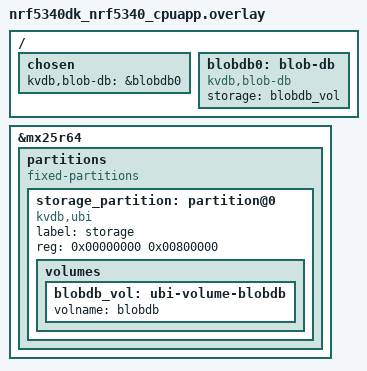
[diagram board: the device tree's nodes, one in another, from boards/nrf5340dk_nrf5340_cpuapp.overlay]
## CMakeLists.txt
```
#-------------------------------------------------------------------------------
# blob_db performance benchmark app
#
# Copyright (c) 2026
# SPDX-License-Identifier: Apache-2.0

cmake_minimum_required(VERSION 3.13.1)
find_package(Zephyr REQUIRED HINTS $ENV{ZEPHYR_BASE})

project(app_perf LANGUAGES C)

target_sources(app PRIVATE src/main.c)
```

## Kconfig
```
# blob_db perf app — Kconfig entry point.

menu "Zephyr"
source "Kconfig.zephyr"
endmenu

module = APP_PERF
module-str = APP_PERF
source "subsys/logging/Kconfig.template.log_config"

config APP_PERF_N_OPS
	int "Number of add/read operations per run"
	default 100
	range 10 1000
	help
	  Size of the benchmark: this many nodes are added (then read back
	  by traversal). Runtime grows roughly linearly.

config APP_PERF_VAL_LEN
	int "Per-node payload size in bytes"
	default 24
	range 0 240
	help
	  Payload bytes stored in each list node (in addition to the 8-byte
	  next_id header). Keep the total node size under
	  CONFIG_BLOB_DB_MAX_PAYLOAD_LEN.

if BLOB_DB_LARGE_PAYLOADS

config APP_PERF_OBJ_LEN
	int "Large-object size in bytes"
	default 65536
	help
	  Size of each object in the large-object phases. Must be within
	  CONFIG_BLOB_DB_MAX_OBJECT_LEN. Run the app twice with different
	  values to see the size sweep that matters: partial-write cost should
	  stay flat while whole-object rewrite cost grows with this number.

config APP_PERF_N_LARGE
	int "Number of large objects"
	default 4
	range 1 64
	help
	  Kept small: each object costs OBJ_LEN of writes per phase, and on
	  64 KB-sector QSPI NOR a cold pass also pays a sector erase per
	  segment bucket.

config APP_PERF_N_PART
	int "Number of partial (pread/pwrite) operations per phase"
	default 32
	range 4 4096
	help
	  Timing is at millisecond resolution, so this needs to be large
	  enough that a phase totals tens of milliseconds. On real NOR one
	  partial write is tens of ms, so 32 is already seconds; on native_sim
	  without CONFIG_FLASH_SIMULATOR_SIMULATE_TIMING raise it substantially
	  or the phase rounds to zero.

config APP_PERF_PART_LEN
	int "Bytes touched by each partial operation"
	default 64
	range 1 4096
	help
	  Deliberately far smaller than a segment: the point of the partial
	  phases is the ratio between touching a few bytes and rewriting the
	  whole object.

endif # BLOB_DB_LARGE_PAYLOADS
```

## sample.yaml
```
sample:
  description: blob_db performance benchmark
  name: blob-db-perf
common:
  build_only: true
tests:
  perf.default: {}
```

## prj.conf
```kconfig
CONFIG_LOG=y
CONFIG_APP_PERF_LOG_LEVEL_INF=y

# blob_db is switched on by the kvdb,blob-db node in boards/<board>.overlay.

# Keep blob_db quiet so the timing loop is not perturbed by per-op log
# messages (and UART overrun does not eat the benchmark line).
CONFIG_BLOB_DB_LOG_LEVEL_WRN=y

# blob_db stack-allocates a slot buffer per op; roomy main stack keeps
# native_sim's frame overhead safe alongside it.
CONFIG_MAIN_STACK_SIZE=32768

# Exercise the large-object paths (segmented storage, pread, pwrite) as well
# as the small-blob ones. Raises BLOB_DB_MAX_PAYLOAD_LEN's default to 2016 and
# bumps the on-flash format major to 2 — neither affects the small-blob phases,
# whose slot sizes follow the payload actually written.
CONFIG_BLOB_DB_LARGE_PAYLOADS=y

# Count flash operations and bytes. On native_sim this is the only meaningful
# output the benchmark has — the flash simulator models no latency, so every
# wall-clock figure rounds to zero.
CONFIG_BLOB_DB_IOSTATS=y
```

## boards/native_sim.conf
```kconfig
# blob_db_erase_all() invalidates bucket headers by programming 0x00 over
# already-programmed magic bytes (1->0 only — legal on real NOR without an
# erase). The flash simulator rejects program-over-non-erased by default;
# allow it so the benchmark's erase_all-between-phases works on native_sim.
CONFIG_FLASH_SIMULATOR_DOUBLE_WRITES=y

# UBI static PEB pool: native_sim's 8 MB partition in the simulator's default
# 4 KB erase blocks is 2048 PEBs, less the 2 reserved for headers.
CONFIG_UBI_MAX_NR_OF_DATA_PEBS=2046
```

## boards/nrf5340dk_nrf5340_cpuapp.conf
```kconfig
CONFIG_BLOB_DB_SECTOR_BUF_SIZE=65536

# zephyr-ubi's heap: 8 B per erase block (128 of 64 KB here, so 1 KB) plus a
# handle and scratch buffer at attach and a second pair during a format. The
# default assumes 4 KB blocks and would reserve 20 KB.
CONFIG_HEAP_MEM_POOL_ADD_SIZE_BLOB_DB_UBI=6144
```

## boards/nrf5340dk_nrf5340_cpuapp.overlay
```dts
/*
 * Same partition move as the demo app: run the benchmark against the on-board
 * MX25R64 QSPI NOR (8 MB, 64 KB sectors) so the numbers reflect real flash.
 */

/delete-node/ &storage_partition;

&mx25r64 {
	partitions {
		compatible = "fixed-partitions";
		#address-cells = <1>;
		#size-cells = <1>;

		storage_partition: partition@0 {
			compatible = "kvdb,ubi";
			label = "storage";
			reg = <0x00000000 0x00800000>;

			volumes {
				blobdb_vol: ubi-volume-blobdb {
					volname = "blobdb";
				};
			};
		};
	};
};

/*
 * The blob_db store on the volume above. No "automount": this program mounts,
 * formats and unmounts the store itself, which keeps working exactly as
 * before (doc/proposals/2026-10-12-devicetree-configuration.md §3.5).
 */
/ {
	chosen {
		kvdb,blob-db = &blobdb0;
	};

	blobdb0: blob-db {
		compatible = "kvdb,blob-db";
		storage = <&blobdb_vol>;
	};
};
```

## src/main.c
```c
/*
 * Copyright (c) 2026
 * SPDX-License-Identifier: Apache-2.0
 *
 * blob_db performance benchmark.
 *
 * Builds a singly-linked list on top of the blob_db API:
 *   - each node is one blob: { uint64_t next_id; uint8_t val[VAL_LEN]; }
 *   - the head id is stored at BLOB_DB_ROOT_ID (empty root == empty list)
 *
 * Four workloads are measured. Each phase runs erase_all() followed by
 * blob_db_maintain() until nothing is left, so the timed loop measures the
 * append-only write path — the erases blob_db can do ahead are paid up-front
 * and reported separately.
 *   maint   — on flash_area, format every fresh bucket (one 64 KB sector
 *             erase each on mx25r64); on UBI, reclaim the blocks waiting
 *             for an erase. Either way the append/prepend loops below find
 *             an erased block for every bucket they first write.
 *   prepend — alloc_id + bind(new, next=head) + update(root=new_id)
 *   append  — alloc_id + bind(new, next=0) + update(prev_tail, next=new_id)
 *             (O(1) via a caller-side tail cache)
 *   read    — traverse from head, get() every node
 *   update  — rewrite the payload of every existing node in place
 *
 * With CONFIG_BLOB_DB_LARGE_PAYLOADS a second group of phases exercises
 * objects too large for one slot — stored as segments plus an index record —
 * and the partial-access API that exists for them:
 *   lg write   — blob_db_update() of N_LARGE objects of OBJ_LEN each, onto
 *                unformatted buckets, so the sector erases are included
 *   lg rewrite — the same objects written again over now-formatted buckets;
 *                the gap against "lg write" IS the erase cost, measured
 *                rather than assumed
 *   lg read    — blob_db_read() over each object in PART_LEN windows
 *   lg pread   — N_PART reads at pseudo-random offsets, reported per quartile
 *                of the object. Contract R2 says cost is independent of
 *                offset; four similar numbers support that, a rising series
 *                falsifies it
 *   lg pwrite  — N_PART partial writes at pseudo-random offsets. Compare
 *                us/op against "lg rewrite": that ratio is the whole reason
 *                blob_db_write exists, and it should grow with OBJ_LEN
 *                (rewrite) while staying flat (pwrite)
 *
 * Wall-clock is via k_uptime_delta(); ops/sec is derived at millisecond
 * resolution — for flash operations that costs less than 1 % vs a raw
 * cycle counter, and stays sane over runs measured in seconds.
 *
 * CAVEAT for native_sim: the flash simulator does not model erase or program
 * latency unless CONFIG_FLASH_SIMULATOR_SIMULATE_TIMING is set with the
 * MIN_*_TIME_US knobs calibrated to the target part. Without that, these
 * phases measure CPU and memcpy, not storage — which will flatter paths that
 * move fewer bytes and penalise paths that issue more transactions. Run on
 * hardware, or calibrate the simulator, before drawing conclusions.
 */

#include <errno.h>
#include <inttypes.h>
#include <stdint.h>
#include <string.h>

#include <zephyr/kernel.h>
#include <zephyr/logging/log.h>
#include <zephyr/sys/printk.h>

#include <app/lib/blob_db.h>
#include <app/lib/blob_db_iostats.h>

#include <zephyr/app_version.h>

#ifdef CONFIG_ARCH_POSIX
#include "posix_board_if.h"   /* posix_exit() — end the sim run cleanly */
#endif

LOG_MODULE_REGISTER(app_perf, CONFIG_APP_PERF_LOG_LEVEL);

#define N_OPS   CONFIG_APP_PERF_N_OPS
#define VAL_LEN CONFIG_APP_PERF_VAL_LEN

struct __packed node {
	uint64_t next_id;
	uint8_t  val[VAL_LEN];
};

BUILD_ASSERT(sizeof(struct node) <= CONFIG_BLOB_DB_MAX_PAYLOAD_LEN,
	     "node exceeds CONFIG_BLOB_DB_MAX_PAYLOAD_LEN");

/* --- list ops on top of blob_db --------------------------------------- */

static int list_head(uint64_t *head_out)
{
	uint64_t head = 0;
	size_t got;
	int rc = blob_db_get(BLOB_DB_ROOT_ID, &head, sizeof(head), &got);

	if (rc < 0) {
		return rc;
	}
	*head_out = (got == sizeof(head)) ? head : 0;
	return 0;
}

static int list_prepend(uint64_t new_id, const uint8_t *val)
{
	uint64_t head;
	int rc = list_head(&head);

	if (rc < 0) {
		return rc;
	}

	struct node n = { .next_id = head };

	memcpy(n.val, val, VAL_LEN);

	rc = blob_db_update(new_id, &n, sizeof(n));
	if (rc < 0) {
		return rc;
	}
	return blob_db_update(BLOB_DB_ROOT_ID, &new_id, sizeof(new_id));
}

/* Append `new_id` after `prev_tail`, or at the head if the list is empty.
 * Two flash writes per call (same as prepend); the caller keeps track of
 * the current tail to avoid an O(n) walk on every append. */
static int list_append(uint64_t new_id, uint64_t prev_tail, const uint8_t *val)
{
	struct node n = { .next_id = 0 };

	memcpy(n.val, val, VAL_LEN);

	int rc = blob_db_update(new_id, &n, sizeof(n));

	if (rc < 0) {
		return rc;
	}

	if (prev_tail == 0) {
		/* Empty list — new node becomes the head. */
		return blob_db_update(BLOB_DB_ROOT_ID, &new_id, sizeof(new_id));
	}

	/* Splice new_id in after prev_tail. */
	struct node prev;
	size_t got;

	rc = blob_db_get(prev_tail, &prev, sizeof(prev), &got);
	if (rc < 0) {
		return rc;
	}
	prev.next_id = new_id;
	return blob_db_update(prev_tail, &prev, sizeof(prev));
}

/* Returns number of nodes visited (0 on empty list, negative on error). */
static int list_traverse(uint32_t *checksum_out)
{
	uint64_t cur;
	int rc = list_head(&cur);

	if (rc < 0) {
		return rc;
	}

	uint32_t sum = 0;
	int n = 0;

	while (cur != 0) {
		struct node node;
		size_t got;

		rc = blob_db_get(cur, &node, sizeof(node), &got);
		if (rc < 0) {
			return rc;
		}
		if (got != sizeof(node)) {
			LOG_ERR("bad node at id=%llu got=%zu", cur, got);
			return -EIO;
		}
		/* Fold the payload into a checksum so the compiler cannot
		 * elide the reads. */
		for (size_t i = 0; i < VAL_LEN; i++) {
			sum = sum * 33u + node.val[i];
		}
		n++;
		cur = node.next_id;
	}
	if (checksum_out) {
		*checksum_out = sum;
	}
	return n;
}

/* --- benchmark harness ------------------------------------------------- */

/* Run blob_db_maintain() until nothing is left; returns the steps taken. */
static int maintain_all(void)
{
	struct blob_db_maint_result res;
	int steps = 0;

	do {
		const int rc = blob_db_maintain(1, &res);

		if (rc < 0) {
			return rc;
		}
		steps += (int)res.performed;
	} while (res.more);
	return steps;
}

static void bench_line(const char *what, int ops, int64_t ms)
{
	/* Print ops/s with three fractional digits so sub-1-op/s workloads
	 * (e.g. a cold add pass on QSPI) still show a meaningful number. */
	uint64_t milli_ops_per_s =
		(ms > 0) ? (uint64_t)ops * 1000000ULL / (uint64_t)ms : 0;
	uint64_t us_per_op =
		(ops > 0) ? (uint64_t)ms * 1000ULL / (uint64_t)ops : 0;

	printk("bench %-6s : %4d ops in %7" PRId64 " ms  -> "
	       "%4u.%03u ops/s  (%9llu us/op)\n",
	       what, ops, ms,
	       (unsigned)(milli_ops_per_s / 1000),
	       (unsigned)(milli_ops_per_s % 1000),
	       (unsigned long long)us_per_op);
}

#if defined(CONFIG_BLOB_DB_IOSTATS)
/* Flash actually touched by the phase just measured.
 *
 * On native_sim this is the only meaningful number the benchmark produces: the
 * flash simulator models no latency, so every wall-clock figure rounds to zero.
 * It is also the number that settles arguments wall-clock cannot — amplification
 * is a ratio of bytes, and transaction count is what a serial part charges a
 * fixed cost for. Both are printed because a change can improve one and worsen
 * the other.
 */
static struct blob_db_iostats io_mark;

static void io_reset(void)
{
	blob_db_iostats_get(&io_mark);
}

static void io_line(const char *what, size_t useful_bytes)
{
	struct blob_db_iostats now;

	blob_db_iostats_get(&now);

	const uint32_t rd = now.reads - io_mark.reads;
	const uint32_t wr = now.writes - io_mark.writes;
	const uint32_t er = now.erases - io_mark.erases;
	const uint64_t brd = now.bytes_read - io_mark.bytes_read;
	const uint64_t bwr = now.bytes_written - io_mark.bytes_written;
	/* Erase BYTES, not just calls: one call may cover one erase block or
	 * the whole partition (blob_db_erase_all() does exactly that), and a
	 * cost model fed only the call count cannot tell those apart. This is
	 * the field app_perf_l0/tools/l0_timing.py needs to charge an erase
	 * per block; captures older than it carry the count alone. */
	const uint64_t ber = now.bytes_erased - io_mark.bytes_erased;

	printk("   io %-10s: rd %6u ops/%8llu B   wr %5u ops/%8llu B   "
	       "er %4u ops/%8llu B",
	       what, rd, (unsigned long long)brd, wr,
	       (unsigned long long)bwr, er, (unsigned long long)ber);

	/* Amplification against the bytes the caller actually asked for. */
	if (useful_bytes > 0) {
		printk("   ampl rd %llu.%02llux wr %llu.%02llux",
		       (unsigned long long)(brd / useful_bytes),
		       (unsigned long long)((brd * 100 / useful_bytes) % 100),
		       (unsigned long long)(bwr / useful_bytes),
		       (unsigned long long)((bwr * 100 / useful_bytes) % 100));
	}
	printk("\n");
}
#else
#define io_reset()            ((void)0)
#define io_line(what, bytes)  ((void)0)
#endif

/* Run every workload from an empty list (erase_all) so timings are
 * apples-to-apples across phases. Returns 0 on success, negative errno on
 * blob_db failures. */
static int bench_phase_read_and_update(uint8_t *val, uint32_t *checksum)
{
	io_reset();
	int64_t t = k_uptime_get();
	int visited = list_traverse(checksum);
	int64_t t_read = k_uptime_delta(&t);

	if (visited < 0) {
		return visited;
	}
	if (visited != N_OPS) {
		LOG_ERR("traverse saw %d, expected %u", visited,
			(unsigned)N_OPS);
	}
	bench_line("read", visited, t_read);
	io_line("read", (size_t)visited * sizeof(struct node));

	/* Warm update: walk again and rewrite every node in place. The
	 * bucket is already formatted, so no sector erase runs. */
	uint64_t cur;
	int rc = list_head(&cur);

	if (rc < 0 || cur == 0) {
		return rc;
	}

	io_reset();
	t = k_uptime_get();
	int updated = 0;

	while (cur != 0) {
		struct node node;
		size_t got;

		rc = blob_db_get(cur, &node, sizeof(node), &got);
		if (rc < 0) {
			return rc;
		}
		node.val[0]++;
		rc = blob_db_update(cur, &node, sizeof(node));
		if (rc < 0) {
			return rc;
		}
		updated++;
		cur = node.next_id;
	}
	int64_t t_upd = k_uptime_delta(&t);

	bench_line("update", updated, t_upd);
	io_line("update", (size_t)updated * sizeof(struct node));

	(void)val;
	return 0;
}

/* --- large-object phases ----------------------------------------------- */
#if defined(CONFIG_BLOB_DB_LARGE_PAYLOADS)

#define OBJ_LEN   CONFIG_APP_PERF_OBJ_LEN
#define N_LARGE   CONFIG_APP_PERF_N_LARGE
#define N_PART    CONFIG_APP_PERF_N_PART
#define PART_LEN  CONFIG_APP_PERF_PART_LEN

BUILD_ASSERT(OBJ_LEN <= CONFIG_BLOB_DB_MAX_OBJECT_LEN,
	     "APP_PERF_OBJ_LEN exceeds CONFIG_BLOB_DB_MAX_OBJECT_LEN");
BUILD_ASSERT(PART_LEN <= OBJ_LEN, "APP_PERF_PART_LEN exceeds OBJ_LEN");

/* Static, not stack: OBJ_LEN is tens of kilobytes. */
static uint8_t g_obj[OBJ_LEN];
static uint8_t g_win[PART_LEN];
static uint64_t g_ids[N_LARGE];

/* Throughput line for the phases where bytes matter more than operations. */
static void bench_bytes(const char *what, int ops, size_t bytes, int64_t ms)
{
	uint64_t kb_per_s =
		(ms > 0) ? (uint64_t)bytes * 1000ULL / 1024ULL / (uint64_t)ms : 0;
	uint64_t us_per_op =
		(ops > 0) ? (uint64_t)ms * 1000ULL / (uint64_t)ops : 0;

	printk("bench %-10s: %4d ops in %7" PRId64 " ms  -> "
	       "%6llu KB/s  (%9llu us/op)\n",
	       what, ops, ms, (unsigned long long)kb_per_s,
	       (unsigned long long)us_per_op);
}

/* Deterministic offsets, so runs are comparable and a regression is not
 * masked by a different random walk. */
static uint32_t lcg(uint32_t *state)
{
	*state = (*state * 1103515245u) + 12345u;
	return *state >> 8;
}

static void fill_obj(uint8_t seed)
{
	for (size_t i = 0; i < OBJ_LEN; i++) {
		g_obj[i] = (uint8_t)((i * 31u + seed) ^ (i >> 8));
	}
}

static int bench_large(void)
{
	int rc;

	printk("\n-- large objects (OBJ_LEN=%u  N_LARGE=%u  N_PART=%u  "
	       "PART_LEN=%u) --\n",
	       (unsigned)OBJ_LEN, (unsigned)N_LARGE, (unsigned)N_PART,
	       (unsigned)PART_LEN);

	rc = blob_db_erase_all();
	if (rc < 0) {
		LOG_ERR("erase_all: %d", rc);
		return rc;
	}

	fill_obj(0x5a);

	/* Cold: buckets are unformatted, so every segment pays a sector erase.
	 * Deliberately NOT maintained — the contrast with the warm pass below
	 * is what quantifies the erase cost. */
	io_reset();
	int64_t t = k_uptime_get();

	for (int i = 0; i < N_LARGE; i++) {
		g_ids[i] = blob_db_alloc_id();
		if (g_ids[i] == 0) {
			LOG_ERR("alloc_id returned 0 at i=%d", i);
			return -EIO;
		}
		rc = blob_db_update(g_ids[i], g_obj, OBJ_LEN);
		if (rc < 0) {
			LOG_ERR("large write %d: %d", i, rc);
			return rc;
		}
	}
	bench_bytes("lg write", N_LARGE, (size_t)N_LARGE * OBJ_LEN,
		    k_uptime_delta(&t));
	io_line("lg write", (size_t)N_LARGE * OBJ_LEN);

	/* Confirm the store agrees about what was written before timing reads. */
	size_t reported = 0;

	rc = blob_db_size(g_ids[0], &reported);
	if (rc < 0 || reported != OBJ_LEN) {
		LOG_ERR("size mismatch: rc=%d got=%zu want=%u", rc, reported,
			(unsigned)OBJ_LEN);
		return (rc < 0) ? rc : -EIO;
	}

	/* Warm: same objects, buckets now formatted. */
	fill_obj(0xa5);
	io_reset();
	t = k_uptime_get();
	for (int i = 0; i < N_LARGE; i++) {
		rc = blob_db_update(g_ids[i], g_obj, OBJ_LEN);
		if (rc < 0) {
			LOG_ERR("large rewrite %d: %d", i, rc);
			return rc;
		}
	}
	const int64_t t_rewrite = k_uptime_delta(&t);

	bench_bytes("lg rewrite", N_LARGE, (size_t)N_LARGE * OBJ_LEN, t_rewrite);
	io_line("lg rewrite", (size_t)N_LARGE * OBJ_LEN);

	/* Sequential read through a small window, checksummed so the reads
	 * cannot be elided and a wrong byte shows up as a wrong sum. */
	uint32_t sum = 0;

	io_reset();
	t = k_uptime_get();
	for (int i = 0; i < N_LARGE; i++) {
		for (size_t off = 0; off < OBJ_LEN; off += PART_LEN) {
			size_t got = 0;

			rc = blob_db_read(g_ids[i], off, g_win, PART_LEN, &got);
			if (rc < 0) {
				LOG_ERR("lg read %d@%zu: %d", i, off, rc);
				return rc;
			}
			for (size_t b = 0; b < got; b++) {
				sum = sum * 33u + g_win[b];
			}
		}
	}
	bench_bytes("lg read", N_LARGE * (int)(OBJ_LEN / PART_LEN),
		    (size_t)N_LARGE * OBJ_LEN, k_uptime_delta(&t));
	io_line("lg read", (size_t)N_LARGE * OBJ_LEN);
	printk("lg read checksum: 0x%08x\n", sum);

	/* Offset independence (contract R2): same operation, four bands of the
	 * object. Similar numbers support the claim; a rising series refutes it. */
	for (int q = 0; q < 4; q++) {
		const size_t base = (size_t)q * (OBJ_LEN / 4);
		const size_t span = (OBJ_LEN / 4) - PART_LEN;
		uint32_t rnd = 0x1234u + (uint32_t)q;
		char label[16];

		io_reset();
		t = k_uptime_get();
		for (int n = 0; n < N_PART; n++) {
			const size_t off = base + (span ? (lcg(&rnd) % span) : 0);
			size_t got = 0;

			rc = blob_db_read(g_ids[n % N_LARGE], off, g_win,
					  PART_LEN, &got);
			if (rc < 0) {
				LOG_ERR("pread q%d: %d", q, rc);
				return rc;
			}
		}
		(void)snprintk(label, sizeof(label), "lg pread q%d", q);
		bench_bytes(label, N_PART, (size_t)N_PART * PART_LEN,
			    k_uptime_delta(&t));
		io_line(label, (size_t)N_PART * PART_LEN);
	}

	/* Partial writes. The number to compare against "lg rewrite": this is
	 * the difference between touching one segment and rewriting the object. */
	uint32_t rnd = 0xbeefu;

	io_reset();
	t = k_uptime_get();
	for (int n = 0; n < N_PART; n++) {
		const size_t off = lcg(&rnd) % (OBJ_LEN - PART_LEN);

		memset(g_win, (uint8_t)n, PART_LEN);
		rc = blob_db_write(g_ids[n % N_LARGE], off, g_win, PART_LEN);
		if (rc < 0) {
			LOG_ERR("pwrite %d: %d", n, rc);
			return rc;
		}
	}
	const int64_t t_pwrite = k_uptime_delta(&t);

	bench_bytes("lg pwrite", N_PART, (size_t)N_PART * PART_LEN, t_pwrite);
	io_line("lg pwrite", (size_t)N_PART * PART_LEN);

	/* Spell the comparison out, since it is the point of the phase. Two
	 * decimals, because integer division reported the DK's real 1.95x as
	 * "1x" — the truncation swallowed the entire result at these
	 * parameters (app_perf/RESULTS.md). */
	if (t_pwrite > 0 && N_PART > 0 && N_LARGE > 0) {
		const uint64_t us_pw =
			(uint64_t)t_pwrite * 1000ULL / (uint64_t)N_PART;
		const uint64_t us_rw =
			(uint64_t)t_rewrite * 1000ULL / (uint64_t)N_LARGE;
		const uint64_t r100 = us_pw ? (us_rw * 100ULL + us_pw / 2) / us_pw
					    : 0;

		printk("partial vs whole-object write: %llu us vs %llu us/op"
		       "  (%llu.%02llux)\n",
		       (unsigned long long)us_pw, (unsigned long long)us_rw,
		       (unsigned long long)(r100 / 100),
		       (unsigned long long)(r100 % 100));
	}

	/* Objects must still read back correctly after all that. */
	rc = blob_db_size(g_ids[0], &reported);
	if (rc < 0 || reported != OBJ_LEN) {
		LOG_ERR("size after pwrite: rc=%d got=%zu", rc, reported);
		return (rc < 0) ? rc : -EIO;
	}
	printk("lg objects intact (%u B each)\n", (unsigned)reported);
	return 0;
}
#endif /* CONFIG_BLOB_DB_LARGE_PAYLOADS */

int main(void)
{
	printk("blob_db perf %s  (N_OPS=%u  VAL_LEN=%u  node=%u B)\n",
	       APP_VERSION_STRING, (unsigned)N_OPS, (unsigned)VAL_LEN,
	       (unsigned)sizeof(struct node));

	int rc = blob_db_mount();

	if (rc < 0) {
		LOG_ERR("mount: %d", rc);
		goto out;
	}

	uint8_t val[VAL_LEN];

	for (size_t i = 0; i < VAL_LEN; i++) {
		val[i] = (uint8_t)i;
	}

	/* ============ prepend phase ==================================== */
	rc = blob_db_erase_all();
	if (rc < 0) {
		LOG_ERR("erase_all: %d", rc);
		goto out;
	}

	int64_t tp = k_uptime_get();
	int maintained = maintain_all();

	if (maintained < 0) {
		LOG_ERR("maintain: %d", maintained);
		goto out;
	}
	bench_line("maint", maintained, k_uptime_delta(&tp));

	int64_t t0 = k_uptime_get();

	for (int i = 0; i < N_OPS; i++) {
		uint64_t id = blob_db_alloc_id();

		if (id == 0) {
			LOG_ERR("alloc_id returned 0 at i=%d", i);
			goto out;
		}
		val[0] = (uint8_t)i;
		rc = list_prepend(id, val);
		if (rc < 0) {
			LOG_ERR("prepend %d: %d", i, rc);
			goto out;
		}
	}
	bench_line("prepend", N_OPS, k_uptime_delta(&t0));

	uint32_t sum = 0;

	rc = bench_phase_read_and_update(val, &sum);
	if (rc < 0) {
		goto out;
	}
	printk("prepend checksum: 0x%08x\n", sum);

	/* ============ append phase ===================================== */
	rc = blob_db_erase_all();
	if (rc < 0) {
		LOG_ERR("erase_all: %d", rc);
		goto out;
	}

	tp = k_uptime_get();
	maintained = maintain_all();
	if (maintained < 0) {
		LOG_ERR("maintain: %d", maintained);
		goto out;
	}
	bench_line("maint", maintained, k_uptime_delta(&tp));

	int64_t t1 = k_uptime_get();
	uint64_t tail = 0;   /* caller-side tail cache; O(1) append */

	for (int i = 0; i < N_OPS; i++) {
		uint64_t id = blob_db_alloc_id();

		if (id == 0) {
			LOG_ERR("alloc_id returned 0 at i=%d", i);
			goto out;
		}
		val[0] = (uint8_t)i;
		rc = list_append(id, tail, val);
		if (rc < 0) {
			LOG_ERR("append %d: %d", i, rc);
			goto out;
		}
		tail = id;
	}
	bench_line("append", N_OPS, k_uptime_delta(&t1));

	sum = 0;
	rc = bench_phase_read_and_update(val, &sum);
	if (rc < 0) {
		goto out;
	}
	printk("append checksum:  0x%08x\n", sum);

#if defined(CONFIG_BLOB_DB_LARGE_PAYLOADS)
	rc = bench_large();
	if (rc < 0) {
		LOG_ERR("large-object phases: %d", rc);
	}
#endif

out:
	blob_db_unmount();
#ifdef CONFIG_ARCH_POSIX
	posix_exit(rc == 0 ? 0 : 1);
#endif
	return 0;
}
```
